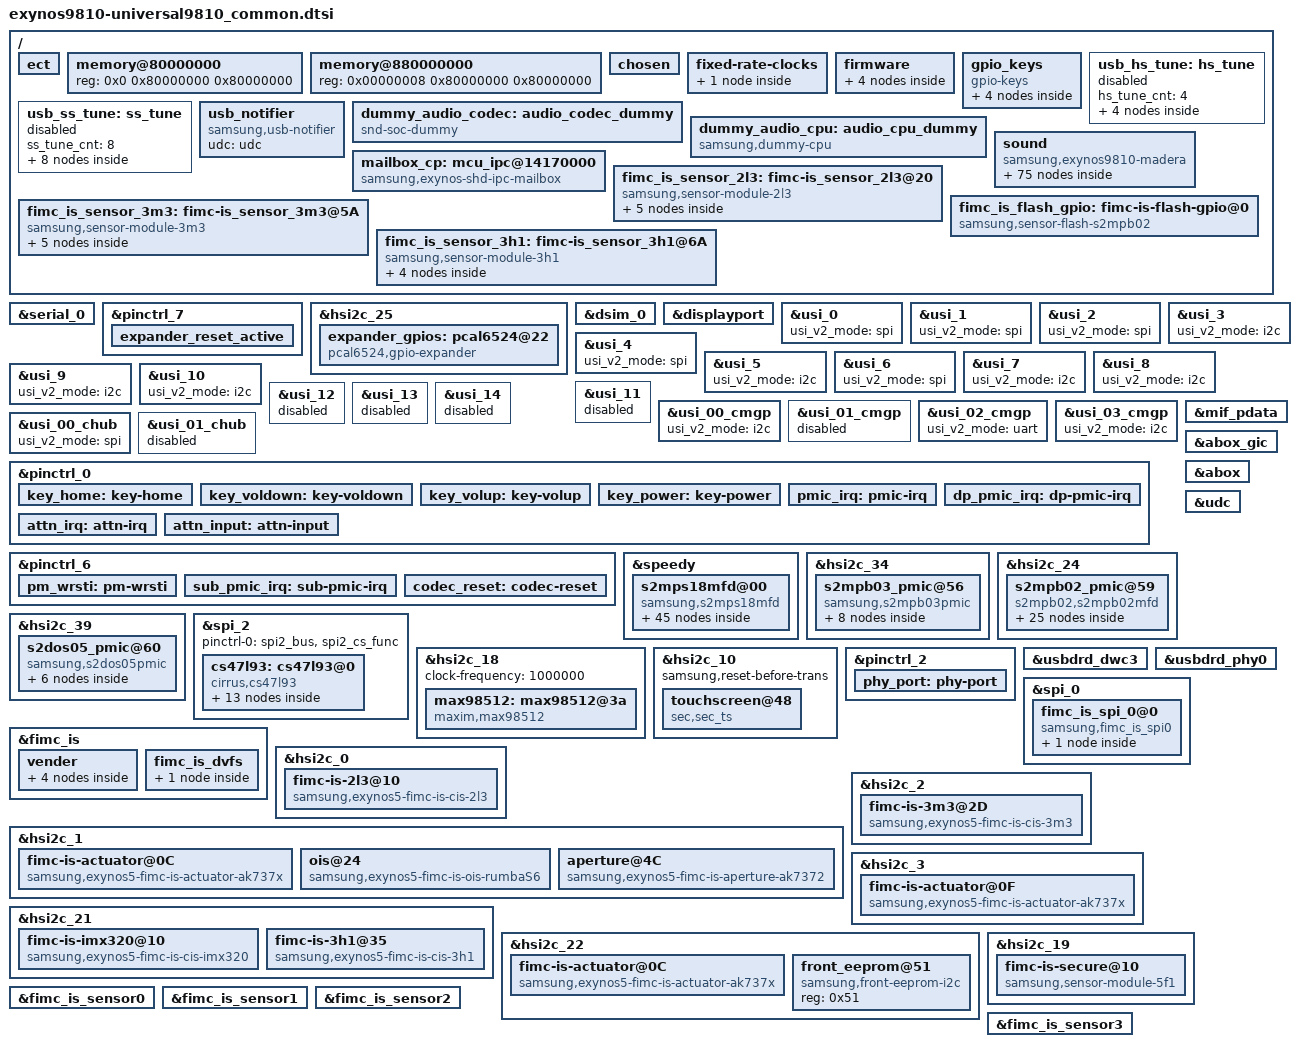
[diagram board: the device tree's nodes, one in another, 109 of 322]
/*
 * SAMSUNG EXYNOS9810 board device tree source
 *
 * Copyright (c) 2017 Samsung Electronics Co., Ltd.
 *		http://www.samsung.com
 *
 * This program is free software; you can redistribute it and/or modify
 * it under the terms of the GNU General Public License version 2 as
 * published by the Free Software Foundation.
*/

#include <dt-bindings/clock/exynos9810.h>
#include <dt-bindings/interrupt-controller/exynos9810.h>
#include <dt-bindings/camera/fimc_is.h>
#include "exynos9810-display-lcd.dtsi"
#include "modem-ss360ap-sipc-pdata.dtsi"

/ {
	fragment@common {
		target-path = "/";
		__overlay__ {
			#address-cells = <2>;
			#size-cells = <1>;
			ect {
				parameter_address = <0x90000000>;
				parameter_size = <0x32000>;
			};

			memory@80000000 {
				device_type = "memory";
				reg = <0x0 0x80000000 0x80000000>;
			};

			memory@880000000 {
				device_type = "memory";
				reg = <0x00000008 0x80000000 0x80000000>;
			};

			chosen {
//				bootargs = "earlycon=exynos4210,0x10440000 console=ttySAC0,115200n8 root=/dev/ram0 console=ttySAC0,115200n8 root=/dev/ram0 rw ramdisk=8192 initrd=0x84000000,8M init=/linuxrc clk_ignore_unused ess_setup=0x86000000";
//				bootargs = "console=ttySAC0 root=/dev/ram0 clk_ignore_unused androidboot.hardware=samsungexynos9810 androidboot.selinux=permissive androidboot.debug_level=0x4948 ecd_setup=disable pmic_info=0x3 ccic_info=0x1 firmware_class.path=/vendor/firmware reserve-fimc=0xffffff80fa000000 sec_debug.cp=0";
				bootargs = "console=ram root=/dev/ram0 clk_ignore_unused androidboot.hardware=samsungexynos9810 androidboot.selinux=permissive androidboot.debug_level=0x4948 ecd_setup=disable pmic_info=0x3 ccic_info=0x1 firmware_class.path=/vendor/firmware reserve-fimc=0xffffff80fa000000 sec_debug.cp=0";
				linux,initrd-start = <0x84000000>;
				linux,initrd-end = <0x841FFFFF>;
			};

			fixed-rate-clocks {
				oscclk {
					compatible = "samsung,exynos9810-oscclk";
					clock-frequency = <26000000>;
				};
			};
			firmware {
				android {
					compatible = "android,firmware";
					fstab {
						compatible = "android,fstab";
						system {
							compatible = "android,system";
							dev = "/dev/block/platform/11120000.ufs/by-name/system";
							type = "ext4";
							mnt_flags = "ro";
							fsmgr_flags = "wait";
						};
						vendor {
							compatible = "android,vendor";
							dev = "/dev/block/platform/11120000.ufs/by-name/vendor";
							type = "ext4";
							mnt_flags = "ro";
							fsmgr_flags = "wait";
						};
					};
				};
			};

			gpio_keys {
				status = "okay";
				compatible = "gpio-keys";
				pinctrl-names = "default";
				pinctrl-0 = <&key_home &key_voldown &key_volup &key_power>;
				button@1 {
					label = "gpio-keys: KEY_HOME";
					linux,code = <172>;
					gpios = <&gpa0 6 0xf>;
					gpio-key,wakeup = <1>;
				};
				button@2 {
					label = "gpio-keys: KEY_VOLUMEDOWN";
					linux,code = <114>;
					gpios = <&gpa0 4 0xf>;
				};
				button@3 {
					label = "gpio-keys: KEY_VOLUMEUP";
					linux,code = <115>;
					gpios = <&gpa0 3 0xf>;
				};
				button@4 {
					label = "gpio-keys: KEY_POWER";
					linux,code = <116>;
					gpios = <&gpa2 4 0xf>;
					gpio-key,wakeup = <1>;
				};
			};

			usb_hs_tune:hs_tune {
				status = "disabled";
				hs_tune_cnt = <4>;
				/* value = <device host> */
				hs_tune1 {
					tune_name = "tx_pre_emp";
					tune_value = <0x3 0x3>;
				};

				hs_tune2 {
					tune_name = "tx_vref";
					tune_value = <0x7 0x7>;
				};

				hs_tune3 {
					tune_name = "rx_sqrx";
					tune_value = <0x5 0x5>;
				};

				hs_tune4 {
					tune_name = "utmi_clk";
					tune_value = <0x1 0x1>;
				};
			};

			usb_ss_tune:ss_tune {
				status = "disabled";
				ss_tune_cnt = <8>;
				/* value = <device host> */
				ss_tune1 {
					tune_name = "sstx_deemph";
					tune_value = <0x6 0x6>;
				};

				ss_tune2 {
					tune_name = "sstx_amp";
					tune_value = <0x0 0x0>;
				};

				ss_tune3 {
					tune_name = "ssrx_los";
					tune_value = <0x4 0x4>;
				};

				ss_tune4 {
					tune_name = "ssrx_ctle_peak";
					tune_value = <0x7 0x7>;
				};

				ss_tune5 {
					tune_name = "ssrx_eq_code";
					tune_value = <0x5 0x5>;
				};

				ss_tune6 {
					tune_name = "ssrx_cur_ctrl";
					tune_value = <0x0 0x0>;
				};

				ss_tune7 {
					tune_name = "ssrx_eqen";
					tune_value = <0x3 0x3>;
				};

				ss_tune8 {
					tune_name = "sstx_boost";
					tune_value = <0x2 0x2>;
				};

			};

			usb_notifier {
				compatible = "samsung,usb-notifier";
				udc = <&udc>;
			};

			dummy_audio_codec: audio_codec_dummy {
				status = "okay";
				compatible = "snd-soc-dummy";
			};

			dummy_audio_cpu: audio_cpu_dummy {
				compatible = "samsung,dummy-cpu";
				status = "okay";
			};

			sound {
				status = "okay";
				compatible = "samsung,exynos9810-madera";

				clock-names = "xclkout";
				clocks = <&clock OSC_AUD>;

				cirrus,sysclk = <1 4 98304000>;
				cirrus,dspclk = <8 4 147456000>;
				cirrus,fll1-refclk = <1 0 26000000>;

				cirrus,asyncclk = <2 5 90316800>;
				cirrus,fll2-refclk = <2 1 32768>;

				samsung,routing = "HEADSETMIC", "MICBIAS2A",
					"IN1BL", "HEADSETMIC",
					"DMIC1", "MICBIAS1A",
					"IN3L", "DMIC1",
					"DMIC2", "MICBIAS1B",
					"IN2AL", "DMIC2",
					"DMIC3", "MICBIAS1C",
					"IN3R", "DMIC3",
					"VTS PAD DPDM", "DMIC1",
					"RECEIVER", "HPOUT4L",
					"RECEIVER", "HPOUT4R",
					"HEADPHONE", "HPOUT2L",
					"HEADPHONE", "HPOUT2R",
					"BLUETOOTH SPK", "ABOX UAIF3 Playback",
					"ABOX UAIF3 Capture", "BLUETOOTH MIC",
					"VOUTPUT", "ABOX UAIF0 Playback",
					"ABOX UAIF1 Capture", "VINPUT1",
					"SPEAKER", "HiFi Playback",
					"VOUTPUTCALL", "ABOX UAIF2 Playback",
					"ABOX UAIF2 Capture", "VINPUTCALL",
					"VTS Virtual Output", "VTS Virtual Output Mux",
					"VTS Virtual Output Mux", "DMIC1";

				samsung,codec = <&abox &abox_uaif_0 &abox_uaif_1 &abox_uaif_2
					&abox_uaif_3 &abox_dsif &vts>;
				samsung,aux = <&abox_effect>;

				rdma@0 {
					cpu {
						sound-dai = <&abox 0>;
					};
					codec {
						sound-dai = <&dummy_audio_codec>;
					};
				};
				rdma@1 {
					cpu {
						sound-dai = <&abox 1>;
					};
					codec {
						sound-dai = <&dummy_audio_codec>;
					};
				};
				rdma@2 {
					cpu {
						sound-dai = <&abox 2>;
					};
					codec {
						sound-dai = <&dummy_audio_codec>;
					};
				};
				rdma@3 {
					cpu {
						sound-dai = <&abox 3>;
					};
					codec {
						sound-dai = <&dummy_audio_codec>;
					};
				};
				rdma@4 {
					cpu {
						sound-dai = <&abox 4>;
					};
					codec {
						sound-dai = <&dummy_audio_codec>;
					};
				};
				rdma@5 {
					cpu {
						sound-dai = <&abox 5>;
					};
					codec {
						sound-dai = <&dummy_audio_codec>;
					};
				};
				rdma@6 {
					cpu {
						sound-dai = <&abox 6>;
					};
					codec {
						sound-dai = <&dummy_audio_codec>;
					};
				};
				rdma@7 {
					cpu {
						sound-dai = <&abox 7>;
					};
					codec {
						sound-dai = <&dummy_audio_codec>;
					};
				};
				wdma@0 {
					cpu {
						sound-dai = <&abox 8>;
					};
					codec {
						sound-dai = <&dummy_audio_codec>;
					};
				};
				wdma@1 {
					cpu {
						sound-dai = <&abox 9>;
					};
					codec {
						sound-dai = <&dummy_audio_codec>;
					};
				};
				wdma@2 {
					cpu {
						sound-dai = <&abox 10>;
					};
					codec {
						sound-dai = <&dummy_audio_codec>;
					};
				};
				wdma@3 {
					cpu {
						sound-dai = <&abox 11>;
					};
					codec {
						sound-dai = <&dummy_audio_codec>;
					};
				};
				wdma@4 {
					cpu {
						sound-dai = <&abox 12>;
					};
					codec {
						sound-dai = <&dummy_audio_codec>;
					};
				};
				vts@0 {
					cpu {
						sound-dai = <&dummy_audio_cpu>;//<&vts 0>;
					};
					codec {
						sound-dai = <&dummy_audio_codec>;
					};
				};
				vts@1 {
					cpu {
						sound-dai = <&dummy_audio_cpu>;//<&vts 1>;
					};
					codec {
						sound-dai = <&dummy_audio_codec>;
					};
				};
				dp_audio@0 {
					cpu {
						sound-dai = <&dummy_audio_cpu>;
					};
					codec {
						sound-dai = <&dummy_audio_codec>;
					};
				};
				uaif@0 {
					cpu {
						sound-dai = <&abox_uaif_0>;
					};
					codec {
						sound-dai = <&cs47l93 0>;
					};
				};
				uaif@1 {
					cpu {
						sound-dai = <&abox_uaif_1>;
					};
					codec {
						sound-dai = <&max98512 0>;
					};
				};
				uaif@2 {
					cpu {
						sound-dai = <&abox_uaif_2>;
					};
					codec {
						sound-dai = <&dummy_audio_codec>;
					};
				};
				uaif@3 {
					cpu {
						sound-dai = <&abox_uaif_3>;
					};
					codec {
						sound-dai = <&dummy_audio_codec>;
					};
				};
				dsif@0 {
					cpu {
						sound-dai = <&abox_dsif>;
					};
					codec {
						sound-dai = <&dummy_audio_codec>;
					};
				};
				sifs0@0 {
					cpu {
						sound-dai = <&abox 13>;
					};
					codec {
						sound-dai = <&dummy_audio_codec>;
					};
				};
				sifs1@0 {
					cpu {
						sound-dai = <&abox 14>;
					};
					codec {
						sound-dai = <&dummy_audio_codec>;
					};
				};
				sifs2@0 {
					cpu {
						sound-dai = <&abox 15>;
					};
					codec {
						sound-dai = <&dummy_audio_codec>;
					};
				};
				debug-trace@1 {
					cpu {
						sound-dai = <&cs47l93 6>;
					};
					codec {
						sound-dai = <&cs47l93 7>;
					};
				};
			};

			mailbox_cp: mcu_ipc@14170000 {
				compatible = "samsung,exynos-shd-ipc-mailbox";
				reg = <0x0 0x14170000 0x180>;
				mcu,name = "mcu_ipc_cp";
				mcu,id = <0>;
				interrupts = <0 INTREQ__MAILBOX_CP2AP 0 >;
				mcu,irq_affinity_mask = <3>;
			};

			/* REAR CAMERA */
			fimc_is_sensor_2l3: fimc-is_sensor_2l3@20 {
				compatible = "samsung,sensor-module-2l3";

				pinctrl-names = "pin0", "pin1", "pin2", "release";
				pinctrl-0 = <>;
				pinctrl-1 = <&fimc_is_mclk0_out>;
				pinctrl-2 = <&fimc_is_mclk0_fn>;
				pinctrl-3 = <>;

				position = <0>;	/* Rear:0. Front:1. Rear_sub:2. Secure:3. */
				id = <0>; /* fimc_is_sensor id */
				mclk_ch = <0>;
				sensor_i2c_ch = <0>; /* SENSOR_CONTROL_I2C0 */

				gpio_mclk = <&gpc1 4 0x1>;
				gpio_reset = <&gpg2 6 0x1>; /* sensor reset */
				gpio_ois_reset = <&gpg0 6 0x1>; /* ois reset */

				status = "okay";

				af {
					product_name = <18>; /* ACTUATOR_NAME_AK737X : ak7371 or ak7374 */
					i2c_ch = <1>; /* SENSOR_CONTROL_I2C1 */
				};

				flash {
					product_name = <11>; /* FLASH_GPIO */
				};

				ois {
					product_name = <2>; /* RUMBA-S6 */
					i2c_addr = <0x48>;
					i2c_ch = <1>; /* SENSOR_CONTROL_I2C1 */
				};

				aperture {
					product_name = <1>; /* ak7372 */
					i2c_addr = <0x98>;
					i2c_ch = <1>; /* SENSOR_CONTROL_I2C1 */
				};

				internal_vc {
					/* vc_list = <channel, data_type, buffer_offset>
					 * channel : Output VC channel
					 *  - Supported channels are 1(VC1), 2(VC2), 3(VC3)
					 *  - Since channel 0(VC0) is dedicated to image data, it can not be used

					 * data_type : Output type of VC channel
					 *  - Value 0 VC_NOTHING
					 *  - Value 1 VC_TAILPDAF
					 *  - Value 2 VC_MIPISTAT
					 *  - Value 3 VC_EMBEDDED
					 * buffer_offset : get_vc_dma_buf offset value of buffer to return when using interface

					 *  - Value 0 N buffer return
					 *  - Value 1 N-1 buffer return
					 */

					vc_list = <2 VC_MIPISTAT 0 3 VC_EMBEDDED 0>; /* channel, type, offset */
				};
			};

			fimc_is_sensor_3m3: fimc-is_sensor_3m3@5A {
				compatible = "samsung,sensor-module-3m3";

				pinctrl-names = "pin0", "pin1", "pin2", "release";
				pinctrl-0 = <>;
				pinctrl-1 = <>;
				pinctrl-2 = <>;
				pinctrl-3 = <>;

				position = <2>; /* Rear:0. Front:1, Tele:2 */
				id = <2>; /* fimc_is_sensor id */
				mclk_ch = <0>;
				sensor_i2c_ch = <2>; /* SENSOR_CONTROL_I2C2 */

				gpio_mclk = <&gpc1 4 0x1>; /* mclk shared with wide-cam */
				gpio_reset = <&gpg2 7 0x1>; /* sensor reset */
				gpio_ois_reset = <&gpg0 6 0x1>; /* ois reset */

				status = "okay";

				af {
					product_name = <18>; /* ACTUATOR_NAME_AK737X : ak7371 or ak7374 */
					i2c_ch = <3>; /* SENSOR_CONTROL_I2C3 */
				};

				flash {
					product_name = <11>; /* FLASH_GPIO */
				};

				preprocessor {
					product_name = <100>; /* NOTHING */
				};

				ois {
					product_name = <2>; /* RUMBA-S6 */
					i2c_addr = <0x48>;
					i2c_ch = <1>; /* I2C 1 */
				};

				internal_vc {
					/* vc_list = <channel, data_type, buffer_offset>
					 * channel : Output VC channel
					 *  - Supported channels are 1(VC1), 2(VC2), 3(VC3)
					 *  - Since channel 0(VC0) is dedicated to image data, it can not be used

					 * data_type : Output type of VC channel
					 *  - Value 0 VC_NOTHING
					 *  - Value 1 VC_TAILPDAF
					 *  - Value 2 VC_MIPISTAT
					 *  - Value 3 VC_EMBEDDED
					 * buffer_offset : get_vc_dma_buf offset value of buffer to return when using interface

					 *  - Value 0 N buffer return
					 *  - Value 1 N-1 buffer return
					 */

					vc_list = <1 VC_TAILPDAF 0>; /* channel, type, offset */
				};
			};

			fimc_is_flash_gpio: fimc-is-flash-gpio@0 {
				compatible = "samsung,sensor-flash-s2mpb02";
				id = <0 2>;
				status = "okay";

				torch-gpio = <&gpg2 4 0x1>;
				flash-gpio = <&gpg3 5 0x1>;
			};

			/* FRONT CAMERA */
			fimc_is_sensor_3h1: fimc-is_sensor_3h1@6A {
				compatible = "samsung,sensor-module-3h1";

				pinctrl-names = "pin0", "pin1", "pin2", "release";
				pinctrl-0 = <>;
				pinctrl-1 = <&fimc_is_mclk1_out>;
				pinctrl-2 = <&fimc_is_mclk1_fn>;
				pinctrl-3 = <>;

				position = <1>;	/* Rear:0. Front:1. Rear_sub:2. Secure:3. */
				id = <1>; /* fimc_is_sensor id */
				mclk_ch = <1>;
				sensor_i2c_ch = <4>; /* SENSOR_CONTROL_I2C4 */

				gpio_mclk = <&gpc1 5 0x1>;
				gpio_reset = <&gpg2 5 0x1>; /* sensor reset */
				status = "okay";

				af {
					product_name = <18>; /* ACTUATOR_NAME_AK737X : ak7372 */
					i2c_ch = <5>; /* SENSOR_CONTROL_I2C5 */
				};

				flash {
					product_name = <100>; /* NOTHING */
				};

				ois {
					product_name = <100>; /* NOTHING */
				};

				internal_vc {
					/* DUMMY */
				};
			};
		}; /* end of __overlay__ */
	}; /* end of fragment */
}; /* end of root */
&serial_0 {
	status = "okay";
};

/***** reference symbol node *****/
&pinctrl_7 {
expander_reset_active: expander_reset_active {
	       samsung,pins = "gpg3-6";
	       samsung,pin-function = <1>;
	       samsung,pin-pud = <0>;
	       samsung,pin-val = <1>;
       };
};

&hsi2c_25 {
	#address-cells = <1>;
	#size-cells = <0>;
	status = "okay";
	expander_gpios: pcal6524@22 {
		compatible = "pcal6524,gpio-expander";
		gpio-controller;
		#gpio-cells = <2>;
		reg = <0x22>;
		pinctrl-names = "expander_reset_setting";
		pinctrl-0 = <&expander_reset_active>;
		pcal6524,gpio_start = <300>;
		pcal6524,ngpio = <24>;
		pcal6524,reset-gpio = <&gpg3 6 0>;
		pcal6524,support_initialize = <1>;
		/* config, 24 ~ 0, 1bit configure[1:input, 0:output]*/
		pcal6524,config = <0xFFFFFF>;    /* P2[11111111] P1[11111111] P0[11111111] */
		/* data_out, 24 ~ 0, 1bit configure[1:high, 0:low]*/
		pcal6524,data_out = <0x000000>;  /* P2[00000000] P1[00000000] P0[00000000] */
		/* pull_reg, 8 ~ 0, 2bit configure[00:no_pull, 01:pull_down, 10:pull_up, 11:not used] */
		pcal6524,pull_reg_p0 = <0x0000>; /* 00 00 00 00 / 00 00 00 00 */
		pcal6524,pull_reg_p1 = <0x0000>; /* 00 00 00 00 / 00 00 00 00 */
		pcal6524,pull_reg_p2 = <0x0000>; /* 00 00 00 00 / 00 00 00 00 */
	};
};

&dsim_0 {
	lcd_info = <&s6e3ha8>;
	/* reset */
	gpios = <&gpa3 4 0x1>;
};

&displayport {
	dp,aux_sw_oe = <&expander_gpios 4 0>;
	dp,sbu_sw_sel = <&expander_gpios 1 0>;
	dp,usb_con_sel = <&gph0 6 0>;

	pinctrl-names = "default";
};

&usi_0 {
	usi_v2_mode = "spi";
	status = "okay";
};

&usi_1 {
	usi_v2_mode = "spi";
	status = "okay";
};

&usi_2 {
	usi_v2_mode = "spi";
	status = "okay";
};

&usi_3 {
	usi_v2_mode = "i2c";
	status = "okay";
};

&usi_4 {
	usi_v2_mode = "spi";
	status = "okay";
};

&usi_5 {
	usi_v2_mode = "i2c";
	status = "okay";
};

&usi_6 {
	usi_v2_mode = "spi";
	status = "okay";
};

&usi_7 {
	usi_v2_mode = "i2c";
	status = "okay";
};

&usi_8 {
	usi_v2_mode = "i2c";
	status = "okay";
};

&usi_9 {
	usi_v2_mode = "i2c";
	status = "okay";
};

&usi_10 {
	usi_v2_mode = "i2c";
	status = "okay";
};

&usi_11 {
	status = "disabled";
};

&usi_12 {
	status = "disabled";
};

&usi_13 {
	status = "disabled";
};

&usi_14 {
	status = "disabled";
};

&usi_00_cmgp {
	usi_v2_mode = "i2c";
	status = "okay";
};

/* USI_01_CMGP */
&usi_01_cmgp {
	status = "disabled";
};

/* USI_02_CMGP */
&usi_02_cmgp {
	usi_v2_mode = "uart";
	status = "okay";
};

/* USI_03_CMGP */
&usi_03_cmgp {
	usi_v2_mode = "i2c";
	status = "okay";
};

/* USI_00_CHUB */
&usi_00_chub {
	usi_v2_mode = "spi";
	status = "okay";
};

/* USI_01_CHUB */
&usi_01_chub {
	status = "disabled";
};

&pinctrl_0 {
	key_home: key-home {
		samsung,pins = "gpa0-6";
		samsung,pin-function = <0xf>;
		samsung,pin-pud = <0>;
		samsung,pin-drv = <0>;
	};

	key_voldown: key-voldown {
		samsung,pins = "gpa0-4";
		samsung,pin-function = <0xf>;
		samsung,pin-pud = <0>;
		samsung,pin-drv = <0>;
	};

	key_volup: key-volup {
		samsung,pins = "gpa0-3";
		samsung,pin-function = <0xf>;
		samsung,pin-pud = <0>;
		samsung,pin-drv = <0>;
	};

	key_power: key-power {
		samsung,pins = "gpa2-4";
		samsung,pin-function = <0xf>;
	};

	pmic_irq: pmic-irq {
		samsung,pins = "gpa0-1";
		samsung,pin-pud = <3>;
		samsung,pin-drv = <3>;
	};

	dp_pmic_irq: dp-pmic-irq {
		samsung,pins = "gpa1-4";
		samsung,pin-function = <0>;
		samsung,pin-pud = <0>;
		samsung,pin-drv = <0>;
	};

	attn_irq: attn-irq {
		samsung,pins = "gpa1-0";
		samsung,pin-function = <0xf>;
		samsung,pin-pud = <0>;
		samsung,pin-drv = <0>;
	};
	attn_input: attn-input {
		samsung,pins = "gpa1-0";
		samsung,pin-function = <0>;
		samsung,pin-pud = <1>;
	};

};

&pinctrl_6 {
	/* Warm reset information from AP */
	pm_wrsti: pm-wrsti {
		samsung,pins = "gpg0-1";
		samsung,pin-con-pdn = <3>;
	};
	sub_pmic_irq: sub-pmic-irq {
		samsung,pins = "gpg2-1";
		samsung,pin-function = <0>;
		samsung,pin-pud = <0>;
		samsung,pin-drv = <0>;
	};

	codec_reset: codec-reset {
		samsung,pins ="gpg1-0";
		samsung,pin-con-pdn =<3>;
		samsung,pin-pud-pdn = <1>;
	};
};

&speedy {
	#address-cells = <1>;
	#size-cells = <0>;
	status = "okay";
	s2mps18mfd@00 {
		compatible = "samsung,s2mps18mfd";
		acpm-ipc-channel = <2>;
		i2c-speedy-address;
		s2mps18,wakeup = "enabled";
		s2mps18,irq-gpio = <&gpa0 1 0>;
		reg = <0x00>;
		interrupts = <1 0 0>;
		interrupt-parent = <&gpa0>;
		pinctrl-names = "default";
		pinctrl-0 = <&pmic_irq &pm_wrsti &smpl_warn>;
		gpios = <&gpg0 3 0>;
		smpl_warn_en = <1>; /* 1 : enable , 0 : disable */
		/* range of smpl_warn_vth */
		/* 0x00 : 2.1V, 0x20 : 2.3V, 0x40 : 2.5V, 0x60 : 2.7V 0x80 : 2.9V */
		/* 0xA0 : 3.1V, 0xC0 : 3.3V, 0xE0 : 3.5V */
		smpl_warn_vth = <0x80>;
		/* LowBat_Hys[4:3] 00(100mV), 01(200mV), 10(300mV), 11(400mV) */
		smpl_warn_hys = <0x00>;
		adc_mode = <1>; /* 0 : disable, 1 : current meter, 2 : power meter */
		adc_sync_mode = <2>; /* 1 : sync mode, 2 : async mode */
		g3d_en = <1>; /* 1 : enable , 0 : disable */
		cpu_ocp_warn_en = <1>; /* 1 : enable, 0 : disable */
		cpu_ocp_warn_reset = <0>; /* 0 : 2 clock, 1 : 32 clock */
		cpu_ocp_warn_lv = <0x0>; /* step : -250mA */
		gpu_ocp_warn_en = <1>; /* 1: enable, 0 : disable */
		gpu_ocp_warn_reset = <1>; /* 0 : 2 clock, 1 : 32 clock */
		gpu_ocp_warn_lv = <0x0>; /* step : -166mA */
		/* RTC: wtsr/smpl */
		wtsr_en = "enabled"; /* enable */
		smpl_en = "enabled"; /* enable */
		wtsr_timer_val = <3>;	/* 1000ms */
		smpl_timer_val = <4>;	/* 500ms */
		check_jigon = <0>; /* do not check jigon */
		/* RTC: If it's first boot, reset rtc to 1/1/2017 12:00:00(Sun) */
		init_time,sec = <0>;
		init_time,min = <0>;
		init_time,hour = <12>;
		init_time,mday = <1>;
		init_time,mon = <0>;
		init_time,year = <117>;
		init_time,wday = <0>;

		regulators {
			buck1_reg: BUCK1 {
				regulator-name = "vdd_mif";
				regulator-min-microvolt = <450000>;
				regulator-max-microvolt = <950000>;
				regulator-always-on;
				regulator-ramp-delay = <12000>;
				regulator-initial-mode = <2>;
			};
			buck2_reg: BUCK2 {
				regulator-name = "vdd_cpucl1";
				regulator-min-microvolt = <450000>;
				regulator-max-microvolt = <1300000>;
				regulator-always-on;
				regulator-ramp-delay = <6000>;
				regulator-initial-mode = <1>;
			};

			buck3_reg: BUCK3 {
				regulator-name = "vdd_cpucl0";
				regulator-min-microvolt = <450000>;
				regulator-max-microvolt = <1300000>;
				regulator-always-on;
				regulator-ramp-delay = <12000>;
				regulator-initial-mode = <1>;
			};

			buck4_reg: BUCK4{
				regulator-name = "vdd_int";
				regulator-min-microvolt = <450000>;
				regulator-max-microvolt = <950000>;
				regulator-always-on;
				regulator-ramp-delay = <12000>;
				regulator-initial-mode = <2>;
			};

			buck5_reg: BUCK5 {
				regulator-name = "vdd_cam";
				regulator-min-microvolt = <450000>;
				regulator-max-microvolt = <950000>;
				regulator-always-on;
				regulator-ramp-delay = <12000>;
				regulator-initial-mode = <2>;
			};

			buck6_reg: BUCK6 {
				regulator-name = "vdd_g3d";
				regulator-min-microvolt = <450000>;
				regulator-max-microvolt = <950000>;
				regulator-always-on;
				regulator-ramp-delay = <12000>;
				regulator-initial-mode = <2>;
			};

			buck7_reg: BUCK7 {
				regulator-name = "vdd_cpucl1_m";
				regulator-min-microvolt = <450000>;
				regulator-max-microvolt = <1300000>;
				regulator-always-on;
				regulator-ramp-delay = <6000>;
				regulator-initial-mode = <1>;
			};

			buck8_reg: BUCK8 {
				regulator-name = "vdd2_mem";
				regulator-min-microvolt = <900000>;
				regulator-max-microvolt = <1300000>;
				regulator-always-on;
				regulator-ramp-delay = <12000>;
				regulator-initial-mode = <3>;
			};

			buck9_reg: BUCK9 {
				regulator-name = "vddq_mem";
				regulator-min-microvolt = <450000>;
				regulator-max-microvolt = <950000>;
				regulator-always-on;
				regulator-ramp-delay = <12000>;
				regulator-initial-mode = <2>;
			};

			buck10_reg: BUCK10 {
				regulator-name = "vdd_lldo1";
				regulator-min-microvolt = <750000>;
				regulator-max-microvolt = <1150000>;
				regulator-always-on;
				regulator-ramp-delay = <12000>;
				regulator-initial-mode = <3>;
			};

			buck11_reg: BUCK11 {
				regulator-name = "vdd_lldo2";
				regulator-min-microvolt = <900000>;
				regulator-max-microvolt = <1300000>;
				regulator-always-on;
				regulator-ramp-delay = <12000>;
				regulator-initial-mode = <3>;
			};

			buck12_reg: BUCK12 {
				regulator-name = "vdd_lldo3";
				regulator-min-microvolt = <1100000>;
				regulator-max-microvolt = <1500000>;
				regulator-always-on;
				regulator-ramp-delay = <12000>;
				regulator-initial-mode = <3>;
			};

			buck13_reg: BUCK13 {
				regulator-name = "vdd_mldo";
				regulator-min-microvolt = <1750000>;
				regulator-max-microvolt = <2150000>;
				regulator-always-on;
				regulator-ramp-delay = <12000>;
				regulator-initial-mode = <3>;
			};

			ldo1_reg: LDO1 {
				regulator-name = "vdd_ldo1";
				regulator-min-microvolt = <700000>;
				regulator-max-microvolt = <950000>;
				regulator-always-on;
				regulator-ramp-delay = <12000>;
				regulator-initial-mode = <3>;
			};

			ldo2_reg: LDO2 {
				regulator-name = "vqmmc";
				regulator-min-microvolt = <1700000>;
				regulator-max-microvolt = <3300000>;
				regulator-ramp-delay = <12000>;
			};

			ldo3_reg: LDO3 {
				regulator-name = "vdd_ldo3";
				regulator-min-microvolt = <1600000>;
				regulator-max-microvolt = <1950000>;
				regulator-always-on;
				regulator-ramp-delay = <12000>;
				regulator-initial-mode = <3>;
			};

			ldo4_reg: LDO4 {
				regulator-name = "vdd_ldo4";
				regulator-min-microvolt = <700000>;
				regulator-max-microvolt = <1100000>;
				regulator-always-on;
				regulator-ramp-delay = <12000>;
				regulator-initial-mode = <1>;
			};

			ldo5_reg: LDO5 {
				regulator-name = "vdd_ldo5";
				regulator-min-microvolt = <1600000>;
				regulator-max-microvolt = <1950000>;
				regulator-always-on;
				regulator-ramp-delay = <12000>;
				regulator-initial-mode = <1>;
			};

			ldo6_reg: LDO6 {
				regulator-name = "vdd_ldo6";
				regulator-min-microvolt = <450000>;
				regulator-max-microvolt = <950000>;
				regulator-always-on;
				regulator-ramp-delay = <12000>;
				regulator-initial-mode = <1>;
			};

			ldo7_reg: LDO7 {
				regulator-name = "vdd_ldo7";
				regulator-min-microvolt = <450000>;
				regulator-max-microvolt = <950000>;
				regulator-always-on;
				regulator-ramp-delay = <12000>;
				regulator-initial-mode = <1>;
			};

			ldo8_reg: LDO8 {
				regulator-name = "vdd_ldo8";
				regulator-min-microvolt = <700000>;
				regulator-max-microvolt = <1300000>;
				regulator-always-on;
				regulator-ramp-delay = <12000>;
				regulator-initial-mode = <1>;
			};

			ldo9_reg: LDO9 {
				regulator-name = "vdd_ldo9";
				regulator-min-microvolt = <1600000>;
				regulator-max-microvolt = <1950000>;
				regulator-always-on;
				regulator-ramp-delay = <12000>;
				regulator-initial-mode = <1>;
			};

			ldo10_reg: LDO10 {
				regulator-name = "vdd_ldo10";
				regulator-min-microvolt = <450000>;
				regulator-max-microvolt = <950000>;
				regulator-always-on;
				regulator-ramp-delay = <12000>;
				regulator-initial-mode = <1>;
			};

			ldo11_reg: LDO11 {
				regulator-name = "vdd_ldo11";
				regulator-min-microvolt = <450000>;
				regulator-max-microvolt = <950000>;
				regulator-always-on;
				regulator-ramp-delay = <12000>;
				regulator-initial-mode = <1>;
			};

			ldo12_reg: LDO12 {
				regulator-name = "vdd_ldo12";
				regulator-min-microvolt = <700000>;
				regulator-max-microvolt = <1100000>;
				regulator-always-on;
				regulator-ramp-delay = <12000>;
				regulator-initial-mode = <1>;
			};

			ldo13_reg: LDO13 {
				regulator-name = "vdd_ldo13";
				regulator-min-microvolt = <1600000>;
				regulator-max-microvolt = <1950000>;
				regulator-always-on;
				regulator-ramp-delay = <12000>;
				regulator-initial-mode = <1>;
			};

			ldo14_reg: LDO14 {
				regulator-name = "vdd_ldo14";
				regulator-min-microvolt = <1700000>;
				regulator-max-microvolt = <3350000>;
				regulator-always-on;
				regulator-ramp-delay = <12000>;
				regulator-initial-mode = <1>;
			};

			ldo22_reg: LDO22 {
				regulator-name = "vdd_ldo22";
				regulator-min-microvolt = <700000>;
				regulator-max-microvolt = <1100000>;
				regulator-ramp-delay = <12000>;
				regulator-initial-mode = <0>;
			};

			ldo30_reg: LDO30 {
				regulator-name = "vdd_ldo30";
				regulator-min-microvolt = <450000>;
				regulator-max-microvolt = <1100000>;
				regulator-always-on;
				regulator-ramp-delay = <12000>;
				regulator-initial-mode = <1>;
			};

			ldo31_reg: LDO31 {
				regulator-name = "vmmc";
				regulator-min-microvolt = <1800000>;
				regulator-max-microvolt = <3375000>;
				regulator-ramp-delay = <12000>;
			};

			ldo32_reg: LDO32 {
				regulator-name = "vdd_ldo32";
				regulator-min-microvolt = <1800000>;
				regulator-max-microvolt = <3375000>;
				regulator-always-on;
				regulator-ramp-delay = <12000>;
				regulator-initial-mode = <2>;
			};

			ldo33_reg: LDO33 {
				regulator-name = "vdd_ldo33";
				regulator-min-microvolt = <1000000>;
				regulator-max-microvolt = <2275000>;
				regulator-always-on;
				regulator-ramp-delay = <12000>;
				regulator-initial-mode = <2>;
			};

			ldo34_reg: LDO34 {
				regulator-name = "vdd_ldo34";
				regulator-min-microvolt = <700000>;
				regulator-max-microvolt = <1300000>;
				regulator-always-on;
				regulator-ramp-delay = <12000>;
				regulator-initial-mode = <2>;
			};

			ldo35_reg: LDO35 {
				regulator-name = "tsp_io";
				regulator-min-microvolt = <1800000>;
				regulator-max-microvolt = <1800000>;
				regulator-boot-on;
			};

			ldo36_reg: LDO36 {
				regulator-name = "vdd_ldo36";
				regulator-min-microvolt = <1800000>;
				regulator-max-microvolt = <3375000>;
				regulator-always-on;
				regulator-ramp-delay = <12000>;
				regulator-initial-mode = <2>;
			};

			ldo37_reg: LDO37 {
				regulator-name = "vdd_ldo37";
				regulator-min-microvolt = <1000000>;
				regulator-max-microvolt = <2275000>;
				regulator-always-on;
				regulator-ramp-delay = <12000>;
				regulator-initial-mode = <2>;
			};

			ldo38_reg: LDO38 {
				regulator-name = "vdd_ldo38";
				regulator-min-microvolt = <1000000>;
				regulator-max-microvolt = <2275000>;
				regulator-always-on;
				regulator-ramp-delay = <12000>;
				regulator-initial-mode = <2>;
			};

			ldo39_reg: LDO39 {
				regulator-name = "VDDD_1.05V_IRIS";
				regulator-min-microvolt = <1000000>;
				regulator-max-microvolt = <1050000>;
			};

			ldo40_reg: LDO40 {
				regulator-name = "VDDA_2.8V_IRIS";
				regulator-min-microvolt = <2800000>;
				regulator-max-microvolt = <2800000>;
			};

			ldo41_reg: LDO41 {
				regulator-name = "VDDIO_1.8V_IRIS";
				regulator-min-microvolt = <1800000>;
				regulator-max-microvolt = <1800000>;
			};

			ldo42_reg: LDO42 {
				regulator-name = "vdd_ldo42";
				regulator-min-microvolt = <1800000>;
				regulator-max-microvolt = <3375000>;
				regulator-always-on;
				regulator-ramp-delay = <12000>;
				regulator-initial-mode = <2>;
			};

			ldo43_reg: LDO43 {
				regulator-name = "tsp_avdd";
				regulator-min-microvolt = <3000000>;
				regulator-max-microvolt = <3000000>;
				regulator-boot-on;
			};

			ldo44_reg: LDO44 {
				regulator-name = "vdd_ldo44";
				regulator-min-microvolt = <1800000>;
				regulator-max-microvolt = <3375000>;
				regulator-always-on;
				regulator-ramp-delay = <12000>;
				regulator-initial-mode = <2>;
			};

			ldo45_reg: LDO45 {
				regulator-name = "vdd_ldo45";
				regulator-min-microvolt = <1800000>;
				regulator-max-microvolt = <3375000>;
				regulator-always-on;
				regulator-ramp-delay = <12000>;
				regulator-initial-mode = <2>;
			};
		};
	};
};

&mif_pdata {
	/* GPIOs for HW REV */
	/* XGPIO27-CP_REV0, XGPIO26-CP_REV1, XGPIO25-CP_REV2, XGPIO24-CP_REV3
	* XGPIO13-AP_REV0, XGPIO12-AP_REV1, XGPIO11-AP_REV2, XGPIO10-AP_REV3
	* XGPIO09-AP_REV3 */
	gpios = <&gpg3 3 0>, <&gpg3 2 0>, <&gpg3 1 0>, <&gpg3 0 0>,
		<&gpg1 5 0>, <&gpg1 4 0>, <&gpg1 3 0>, <&gpg1 2 0>,
		<&gpg1 1 0>;
	pinctrl-names = "default";
};

&hsi2c_34 {
	#address-cells = <1>;
	#size-cells = <0>;
	status = "okay";
	s2mpb03_pmic@56 {
		compatible = "samsung,s2mpb03pmic";
		reg = <0x56>;

		s2mpb03,wakeup;

		regulators {
			__ldo1_reg: s2mpb03-ldo1 {
				regulator-name = "VDDD_1.0V_CAM";
				regulator-min-microvolt = <975000>;
				regulator-max-microvolt = <1025000>;
			};

			__ldo2_reg: s2mpb03-ldo2 {
				regulator-name = "VDDQ_1.1V_CAM";
				regulator-min-microvolt = <1100000>;
				regulator-max-microvolt = <1100000>;
			};

			__ldo3_reg: s2mpb03-ldo3 {
				regulator-name = "VDDIO_1.8V_CAM";
				regulator-min-microvolt = <1800000>;
				regulator-max-microvolt = <1800000>;
			};

			__ldo4_reg: s2mpb03-ldo4 {
				regulator-name = "VDDD_RET_1.0V_CAM";
				regulator-min-microvolt = <700000>;
				regulator-max-microvolt = <1025000>;
			};

			__ldo5_reg: s2mpb03-ldo5 {
				regulator-name = "VDDA_2.15V_CAM";
				regulator-min-microvolt = <2150000>;
				regulator-max-microvolt = <2150000>;
			};

			__ldo6_reg: s2mpb03-ldo6 {
				regulator-name = "VDDA_2.95V_CAM";
				regulator-min-microvolt = <2950000>;
				regulator-max-microvolt = <2950000>;
			};

			__ldo7_reg: s2mpb03-ldo7 {
				regulator-name = "VDD_VM_2.8V_OIS";
				regulator-min-microvolt = <2800000>;
				regulator-max-microvolt = <2800000>;
			};
		};
	};
};

&hsi2c_24 {
	#address-cells = <1>;
	#size-cells = <0>;
	status = "okay";
	s2mpb02_pmic@59 {
		compatible = "s2mpb02,s2mpb02mfd";
		reg = <0x59>;

		s2mpb02,wakeup;
		pinctrl-names = "default";
		pinctrl-0 = <&sub_pmic_irq>;

		regulators {
			_buck1_reg: s2mpb02-buck1 {
				regulator-name = "VDD_EXT_1P3_PB03";
				regulator-min-microvolt = <1300000>;
				regulator-max-microvolt = <1300000>;
				regulator-always-on;
				regulator-boot-on;
			};

			_buck2_reg: s2mpb02-buck2 {
				regulator-name = "VDD_EXT_1P3_PB02";
				regulator-min-microvolt = <1300000>;
				regulator-max-microvolt = <1300000>;
				regulator-always-on;
				regulator-boot-on;
			};

			_buckboost_reg: s2mpb02-bb {
				regulator-name = "VREG_BOOST_BYP";
				regulator-min-microvolt = <2600000>;
				regulator-max-microvolt = <4000000>;
				regulator-always-on;
				regulator-boot-on;
			};

			_ldo1_reg: s2mpb02-ldo1 {
				regulator-name = "S2MPB02_LDO1";
				regulator-min-microvolt = <900000>;
				regulator-max-microvolt = <900000>;
			};

			_ldo2_reg: s2mpb02-ldo2 {
				regulator-name = "S2MPB02_LDO2";
				regulator-min-microvolt = <1000000>;
				regulator-max-microvolt = <1000000>;
			};

			_ldo3_reg: s2mpb02-ldo3 {
				regulator-name = "VDDD_1.05V_SUB";
				regulator-min-microvolt = <1000000>;
				regulator-max-microvolt = <1050000>;
			};

			_ldo4_reg: s2mpb02-ldo4 {
				regulator-name = "S2MPB02_LDO4";
				regulator-min-microvolt = <1200000>;
				regulator-max-microvolt = <1200000>;
			};

			_ldo5_reg: s2mpb02-ldo5 {
				regulator-name = "VDDD_1.05V_VT";
				regulator-min-microvolt = <1000000>;
				regulator-max-microvolt = <1050000>;
			};

			_ldo6_reg: s2mpb02-ldo6 {
				regulator-name = "VDDIO_1.8V_VT";
				regulator-min-microvolt = <1800000>;
				regulator-max-microvolt = <1800000>;
			};

			_ldo7_reg: s2mpb02-ldo7 {
				regulator-name = "VDDIO_1.8V_SUB";
				regulator-min-microvolt = <1800000>;
				regulator-max-microvolt = <1800000>;
			};

			_ldo8_reg: s2mpb02-ldo8 {
				regulator-name = "VDD_HRM_1P8";
				regulator-min-microvolt = <1800000>;
				regulator-max-microvolt = <1800000>;
			};

			_ldo9_reg: s2mpb02-ldo9 {
				regulator-name = "S2MPB02_LDO9";
				regulator-min-microvolt = <1800000>;
				regulator-max-microvolt = <1800000>;
			};

			_ldo10_reg: s2mpb02-ldo10 {
				regulator-name = "VDDD_1.8V_OIS";
				regulator-min-microvolt = <1800000>;
				regulator-max-microvolt = <1800000>;
			};

			_ldo11_reg: s2mpb02-ldo11 {
				regulator-name = "VDDA_2.8V_SUB";
				regulator-min-microvolt = <2800000>;
				regulator-max-microvolt = <2800000>;
			};

			_ldo12_reg: s2mpb02-ldo12 {
				regulator-name = "VDDAF_2.8V_SUB";
				regulator-min-microvolt = <2800000>;
				regulator-max-microvolt = <2800000>;
			};

			_ldo13_reg: s2mpb02-ldo13 {
				regulator-name = "VDDA_2.8V_VT";
				regulator-min-microvolt = <2800000>;
				regulator-max-microvolt = <2800000>;
			};

			_ldo14_reg: s2mpb02-ldo14 {
				regulator-name = "VDDAF_COMMON_CAM";
				regulator-min-microvolt = <3300000>;
				regulator-max-microvolt = <3300000>;
			};

			_ldo15_reg: s2mpb02-ldo15 {
				regulator-name = "VDDD_2.8V_OIS";
				regulator-min-microvolt = <2800000>;
				regulator-max-microvolt = <2800000>;
			};

			_ldo16_reg: s2mpb02-ldo16 {
				regulator-name = "VDDAF_2.8V_VT";
				regulator-min-microvolt = <2800000>;
				regulator-max-microvolt = <2800000>;
			};

			_ldo17_reg: s2mpb02-ldo17 {
				regulator-name = "S2MPB02_LDO17";
				regulator-min-microvolt = <2950000>;
				regulator-max-microvolt = <2950000>;
			};

			_ldo18_reg: s2mpb02-ldo18 {
				regulator-name = "VDD_PROXY_LED_3P3";
				regulator-min-microvolt = <3300000>;
				regulator-max-microvolt = <3300000>;
			};
		};

		torch {
			torch1-gpio = <&gpg2 4 0x1>;
			flash1-gpio = <&gpg3 5 0x1>;

			status = "okay";

			leds1 {
				ledname = "leds-sec1";
				id = <0>;
				brightness = <0xC>; /* Nx100+50 : 1250mA */
				timeout = <0x7>; /* (N+1)x62.5 : 500ms */
				torch_table_enable = <0>;
			};

			leds2 {
				ledname = "torch-sec1";
				id = <1>;
				brightness = <0xC>; /* Nx20 = 240mA */
				timeout = <0xF>;
				torch_table_enable = <1>;
				torch_table = <2 3 3 4 4 7 7 7 9 9>; /* [0],[1],[3],[5],[8] */
			};
		};
	};
};

&hsi2c_39 {
	#address-cells = <1>;
	#size-cells = <0>;
	status = "okay";
	s2dos05_pmic@60 {
		compatible = "samsung,s2dos05pmic";
		reg = <0x60>;
		s2dos05,wakeup;
		pinctrl-names = "default";
		pinctrl-0 = <&dp_pmic_irq>;
		s2dos05,s2dos05_int = <&gpa1 4 0>;
		adc_mode = <1>; /* 0 : disable, 1 : current meter, 2 : power meter */
		adc_sync_mode = <2>; /* 1 : sync mode, 2 : async mode */
		regulators {
			dp_buck: s2dos05-buck1 {
				regulator-name = "vdd1";
				regulator-min-microvolt = <850000>;
				regulator-max-microvolt = <2100000>;
				regulator-always-on;
				regulator-boot-on;
			};
			dp_ldo1: s2dos05-ldo1 {
				regulator-name = "vdd2";
				regulator-min-microvolt = <1500000>;
				regulator-max-microvolt = <2000000>;
				regulator-always-on;
				regulator-boot-on;
			};
			dp_ldo2: s2dos05-ldo2 {
				regulator-name = "vdd3";
				regulator-min-microvolt = <1500000>;
				regulator-max-microvolt = <2000000>;
				regulator-always-on;
				regulator-boot-on;
			};
			dp_ldo3: s2dos05-ldo3{
				regulator-name = "vdd4";
				regulator-min-microvolt = <2700000>;
				regulator-max-microvolt = <3775000>;
				regulator-always-on;
				regulator-boot-on;
			};
			dp_ldo4: s2dos05-ldo4{
				regulator-name = "vdd5";
				regulator-min-microvolt = <2700000>;
				regulator-max-microvolt = <3775000>;
				regulator-always-on;
				regulator-boot-on;
			};
		};
	};
};

&abox_gic {
	status = "okay";
};

&abox {
	status = "okay";
};

&spi_2 {
	#address-cells = <1>;
	#size-cells = <0>;
	status = "okay";
	pinctrl-names = "default";
	pinctrl-0 = <&spi2_bus &spi2_cs_func>;

	cs47l93: cs47l93@0 {
		compatible = "cirrus,cs47l93";
		reg = <0x0>;

		spi-max-frequency = <25000000>;

		interrupts = <2 0 0>;
		interrupt-controller;
		#interrupt-cells = <2>;
		interrupt-parent = <&gpa2>;
		gpio-controller;
		#gpio-cells = <2>;
		#sound-dai-cells = <1>;

		AVDD-supply = <&ldo33_reg>;
		DBVDD1-supply = <&ldo33_reg>;
		CPVDD1-supply = <&ldo33_reg>;
		CPVDD2-supply = <&ldo34_reg>;
		DCVDD-supply = <&ldo34_reg>;

		reset-gpios = <&gpg1 0 0>;

		cirrus,dmic-ref = <1 1 1 1>;
		cirrus,inmode = <
			2 2 1 0 /* IN1 */
			2 2 0 0 /* IN2 */
		>;
		cirrus,outmono = <0 0 0 1 0 0>;

		pinctrl-names = "default";
		pinctrl-0 = <&codec_reset>;

		cirrus,gpsw = <1 0>;

		cs47l93_defaults: cs47l93-gpio-defaults {
			aif1 {
				groups = "aif1";
				function = "aif1";
				bias-bus-hold;
			};

			aif2 {
				groups = "aif2";
				function = "aif2";
				bias-bus-hold;
			};

			aif3 {
				groups = "aif3";
				function = "aif3";
				bias-bus-hold;
			};
		};

		MICBIAS1 {
			regulator-min-microvolt = <1800000>;
			regulator-max-microvolt = <1800000>;
			cirrus,ext-cap = <1>;
		};
		MICBIAS1A {
			regulator-active-discharge = <1>;
		};
		MICBIAS1B {
			regulator-active-discharge = <1>;
		};
		MICBIAS1C {
			regulator-active-discharge = <1>;
		};
		MICBIAS2 {
			regulator-min-microvolt = <2800000>;
			regulator-max-microvolt = <2800000>;
			cirrus,ext-cap = <1>;
		};
		MICBIAS2A {
			regulator-active-discharge = <1>;
		};

		cirrus,accdet {
			#address-cells = <1>;
			#size-cells = <0>;

			acc@1 {
				reg = <1>;

				cirrus,micd-bias-start-time = <0x1>;
				cirrus,micd-rate = <7>;
				cirrus,micd-detect-debounce-ms = <300>;
				cirrus,micd-clamp-mode = <0x8>;
				cirrus,jd-use-jd2;

				cirrus,init-delay-ms = <30>;
				cirrus,micd-dbtime = <0x1>;
				cirrus,micd-timeout-ms = <1000>;
				cirrus,micd-force-micbias;
				cirrus,hpdet-short-circuit-imp = <3>;
				cirrus,micd-pol-gpios = <&cs47l93 4 0>;
				cirrus,micd-ranges = <
					116 226
					173 582
					321 115
					752 114
					1257 217
				>;
				cirrus,micd-software-compare;
				cirrus,micd-open-circuit-declare = <1>;
				cirrus,jd-wake-time = <5000>;

				cirrus,moisture-pin = <7>;
				cirrus,moisture-imp = <2000>;
				cirrus,moisture-debounce = <4>;

				cirrus,micd-configs = <
					0 1 4 0 1
				>;
			};
		};

		controller-data {
			samsung,spi-feedback-delay = <1>;
			samsung,spi-chip-select-mode = <0>;
		};
	};
};

&hsi2c_18 {
	#address-cells = <1>;
	#size-cells = <0>;
	status = "okay";
	clock-frequency = <1000000>;
	max98512: max98512@3a {
		compatible = "maxim,max98512";
		#sound-dai-cells = <1>;
		reg = <0x3a>;
		maxim,spk-gain = <0x05>;
		maxim,sysclk = <12288000>;
		maxim,vmon_slot = <0>;
		maxim,platform_info = <2 0x0 0x0 0x0 0x0 42>;
		maxim,boost_step = <
			0x0F 0x0F 0x0F 0x0F
			0x0F 0x0F 0x0F 0x0F
			0x0F 0x0F 0x0F 0x0F
			0x0F 0x0F 0x02 0x00
			>;
		maxim,adc_threshold = <7>;
		maxim,registers-of-amp =
			<0x1F 0x00>,
			<0x21 0xC0>,
			<0x2D 0x14>,
			<0x2F 0x00>;
		maxim,sub_reg = <0x39>;
		maxim,mono_stereo = <1>;
		interleave_mode = <1>;
	};
};
&hsi2c_10 {
	#address-cells = <1>;
	#size-cells = <0>;
	status = "okay";
	samsung,reset-before-trans;
	touchscreen@48 {
		compatible = "sec,sec_ts";
		reg = <0x48>;
		pinctrl-names = "on_state", "off_state";
		pinctrl-0 = <&attn_irq>;
		pinctrl-1 = <&attn_input>;
		pressure-sensor = "Y";
		sec,irq_gpio = <&gpa1 0 0>;
		sec,irq_type = <8200>;
		sec,max_coords = <4095 4095>;
		sec,mis_cal_check = <1>;
		sec,regulator_dvdd = "tsp_io";
		sec,regulator_avdd = "tsp_avdd";
		sec,regulator_boot_on;
		sec,always_lpmode = <1>;
		//sec,pat_function = <2>;
		//sec,afe_base = <0x0121>;
		sec,project_name = "Star1", "G950";
		sec,firmware_name = "tsp_sec/y761_dream1.fw", "tsp_sec/y761_dream1.fw";
		//support_dex_mode;
	};
};

&pinctrl_2 {
	phy_port: phy-port {
		samsung,pins = "gph0-6";
		samsung,pin-function = <0x0>;
		samsung,pin-pud = <3>;
		samsung,pin-drv = <0>;
	};
};

&udc {
	status = "okay";
};

&usbdrd_dwc3 {
	dr_mode = "otg";
	maximum-speed = "super-speed";
	snps,quirk-frame-length-adjustment = <0x20>;
	snps,u1u2_exitfail_quirk;
	/*
	 * dis-u2-freeclk-exists-quirk, dis_u2_susphy_quirk are alternative.
	 * One of them should be selected
	 */
	/*snps,dis-u2-freeclk-exists-quirk;*/
	snps,dis_u2_susphy_quirk;
};

&usbdrd_phy0 {
	status = "okay";

	pinctrl-names = "default";
	pinctrl-0 = <&phy_port>;
	phy,gpio_phy_port = <&gph0 6 0x0>;
	hs_tune_param = <&usb_hs_tune>;
	ss_tune_param = <&usb_ss_tune>;
};

/* SPI USI_PERIC1_SPI_CAM0 */
&spi_0 {
	#address-cells = <1>;
	#size-cells = <0>;
	pinctrl-names = "default", "spi_out", "spi_fn";
	pinctrl-0 = <&fimc_is_spi_pin0_out>;
	pinctrl-1 = <&fimc_is_spi_pin0_out>;
	pinctrl-2 = <&fimc_is_spi_pin0_fn>;
	status = "okay";

	num-cs = <1>;

	fimc_is_spi_0@0 {
		compatible = "samsung,fimc_is_spi0";
		spi-max-frequency = <50000000>;
		reg = <0x0>;
		pinctrl-names = "default", "ssn_out", "ssn_fn", "ssn_inpd", "ssn_inpu";
		pinctrl-0 = <&fimc_is_spi_ssn0_out>;
		pinctrl-1 = <&fimc_is_spi_ssn0_out>;
		pinctrl-2 = <&fimc_is_spi_ssn0_fn>;
		pinctrl-3 = <&fimc_is_spi_ssn0_inpd>;
		pinctrl-4 = <&fimc_is_spi_ssn0_inpu>;

		use_spi_pinctrl; /* define if camera use spi */

		controller-data {
			samsung,spi-chip-select-mode = <0>;
			samsung,spi-feedback-delay = <1>;
		};
	};
};

&fimc_is {
	vender {
		rear_sensor_id = <36>; /* 2L3 : 36 */
		front_sensor_id = <31>; /* 3H1 : 31 */
		rear_second_sensor_id = <33>; /* 3M3 : 33 */
		secure_sensor_id = <306>; /* 5F1 : 306 */
		use_module_check;
		use_ois;
		/*skip_cal_loading;*/
		check_sensor_vendor;
		ois_sensor_index = <0>;
		aperture_sensor_index = <0>;

		max_camera_num = <4>;
		camera_info0 {			// 0 : rear
			isp = <0>;		/* 0 : INT , 1 : EXT , 2 : SOC */
			cal_memory = <1>;	/* 0 : N , 1 : FROM , 2 : EEPROM , 3 : OTP  */
			read_version = <0>;	/* 0 : SYSFS , 1 : CAMON */
			core_voltage = <0>;	/* 0 : N , 1 : Y  */
			upgrade = <0>;		/* 0 : N , 1 : SYSFS , 2 : CAMON */
			fw_write = <0>;		/* 0 : N,  1 : OS, 2 : SD, 3 : ALL */
			fw_dump = <0>;		/* 0 : N , 1 : Y  */
			companion = <0>;	/* 0 : N , 1 : Y  */
			ois = <1>;		/* 0 : N , 1 : Y  */
			valid = <1>;		/* 0 : INVALID , 1 : VALID   */
		};
		camera_info1 {			// 1 : front
			isp = <0>;		/* 0 : INT , 1 : EXT , 2 : SOC */
			cal_memory = <2>;	/* 0 : N , 1 : FROM , 2 : EEPROM , 3 : OTP  */
			read_version = <0>;	/* 0 : SYSFS , 1 : CAMON */
			core_voltage = <0>;	/* 0 : N , 1 : Y  */
			upgrade = <0>;		/* 0 : N , 1 : SYSFS , 2 : CAMON */
			fw_write = <0>;		/* 0 : N,  1 : OS, 2 : SD, 3 : ALL */
			fw_dump = <0>;		/* 0 : N , 1 : Y  */
			companion = <0>;	/* 0 : N , 1 : Y  */
			ois = <0>;		/* 0 : N , 1 : Y  */
			valid = <1>;		/* 0 : INVALID , 1 : VALID   */
		};
		camera_info2 {			// 2 : tele
			isp = <0>;              /* 0 : INT , 1 : EXT , 2 : SOC */
			cal_memory = <1>;       /* 0 : N , 1 : FROM , 2 : EEPROM , 3 : OTP  */
			read_version = <0>;     /* 0 : SYSFS , 1 : CAMON */
			core_voltage = <0>;     /* 0 : N , 1 : Y  */
			upgrade = <0>;          /* 0 : N , 1 : SYSFS , 2 : CAMON */
			fw_write = <0>;         /* 0 : N,  1 : OS, 2 : SD, 3 : ALL */
			fw_dump = <0>;          /* 0 : N , 1 : Y  */
			companion = <0>;        /* 0 : N , 1 : Y  */
			ois = <1>;              /* 0 : N , 1 : Y  */
			valid = <1>;            /* 0 : INVALID , 1 : VALID   */
		};
		camera_info3 {			// 3 : iris
			isp = <2>;		/* 0 : INT , 1 : EXT , 2 : SOC */
			cal_memory = <0>;	/* 0 : N , 1 : FROM , 2 : EEPROM , 3 : OTP  */
			read_version = <1>;	/* 0 : SYSFS , 1 : CAMON */
			core_voltage = <0>;	/* 0 : N , 1 : Y  */
			upgrade = <0>;		/* 0 : N , 1 : SYSFS , 2 : CAMON */
			fw_write = <0>;		/* 0 : N,  1 : OS, 2 : SD, 3 : ALL */
			fw_dump = <0>;		/* 0 : N , 1 : Y  */
			companion = <0>;	/* 0 : N , 1 : Y  */
			ois = <0>;		/* 0 : N , 1 : Y  */
			valid = <1>;		/* 0 : INVALID , 1 : VALID   */
		};
	};

	fimc_is_dvfs {
		#define DVFS_INT_CAM_L0 690000
		#define DVFS_INT_CAM_L1 680000
		#define DVFS_INT_CAM_L2 670000
		#define DVFS_INT_CAM_L3 660000
		#define DVFS_INT_CAM_L4 650000
		#define DVFS_INT_CAM_L5 640000
		#define DVFS_INT_CAM_L6 630000

		#define DVFS_INT_L0 534000
		#define DVFS_INT_L1 400000
		#define DVFS_INT_L2 336000
		#define DVFS_INT_L3 267000
		#define DVFS_INT_L4 178000
		#define DVFS_INT_L5 107000

		#define DVFS_CAM_L0 690000
		#define DVFS_CAM_L1 680000
		#define DVFS_CAM_L2 670000
		#define DVFS_CAM_L3 660000
		#define DVFS_CAM_L4 650000
		#define DVFS_CAM_L5 640000
		#define DVFS_CAM_L6 630000
		#define DVFS_CAM_L7 620000
		#define DVFS_CAM_L8 610000
		#define DVFS_CAM_L9 600000
		#define DVFS_CAM_L10 590000

		#define DVFS_MIF_L0 2093000
		#define DVFS_MIF_L1 2093000
		#define DVFS_MIF_L2 2002000
		#define DVFS_MIF_L3 1794000
		#define DVFS_MIF_L4 1539000
		#define DVFS_MIF_L5 1352000
		#define DVFS_MIF_L6 1014000
		#define DVFS_MIF_L7 845000
		#define DVFS_MIF_L8 676000
		#define DVFS_MIF_L9 546000
		#define DVFS_MIF_L10 421000

		table0 {
			desc = "dvfs table v0.0 for 12M/8M";

			default_int_cam = <DVFS_INT_CAM_L0>;
			default_cam = <DVFS_CAM_L0>;
			default_mif = <DVFS_MIF_L0>;
			default_int = <DVFS_INT_L5>;
			default_hpg = <1>;

			front_preview_int_cam = <DVFS_INT_CAM_L5>;
			front_preview_cam = <DVFS_CAM_L9>;
			front_preview_mif = <DVFS_MIF_L6>;
			front_preview_int = <DVFS_INT_L5>;
			front_preview_hpg = <1>;

			front_preview_full_int_cam = <DVFS_INT_CAM_L3>;
			front_preview_full_cam = <DVFS_CAM_L9>;
			front_preview_full_mif = <DVFS_MIF_L6>;
			front_preview_full_int = <DVFS_INT_L5>;
			front_preview_full_hpg = <1>;

			front_capture_int_cam = <DVFS_INT_CAM_L3>;
			front_capture_cam = <DVFS_CAM_L9>;
			front_capture_mif = <DVFS_MIF_L6>;
			front_capture_int = <DVFS_INT_L5>;
			front_capture_hpg = <1>;

			front_video_int_cam = <DVFS_INT_CAM_L5>;
			front_video_cam = <DVFS_CAM_L9>;
			front_video_mif = <DVFS_MIF_L6>;
			front_video_int = <DVFS_INT_L5>;
			front_video_hpg = <1>;

			front_video_whd_int_cam = <DVFS_INT_CAM_L5>;
			front_video_whd_cam = <DVFS_CAM_L9>;
			front_video_whd_mif = <DVFS_MIF_L6>;
			front_video_whd_int = <DVFS_INT_L5>;
			front_video_whd_hpg = <1>;

			front_video_capture_int_cam = <DVFS_INT_CAM_L3>;
			front_video_capture_cam = <DVFS_CAM_L8>;
			front_video_capture_mif = <DVFS_MIF_L6>;
			front_video_capture_int = <DVFS_INT_L5>;
			front_video_capture_hpg = <1>;

			front_video_whd_capture_int_cam = <DVFS_INT_CAM_L3>;
			front_video_whd_capture_cam = <DVFS_CAM_L9>;
			front_video_whd_capture_mif = <DVFS_MIF_L6>;
			front_video_whd_capture_int = <DVFS_INT_L5>;
			front_video_whd_capture_hpg = <1>;

			front_vt1_int_cam = <DVFS_INT_CAM_L5>;
			front_vt1_cam = <DVFS_CAM_L9>;
			front_vt1_mif = <DVFS_MIF_L6>;
			front_vt1_int = <DVFS_INT_L5>;
			front_vt1_hpg = <1>;

			front_vt2_int_cam = <DVFS_INT_CAM_L5>;
			front_vt2_cam = <DVFS_CAM_L9>;
			front_vt2_mif = <DVFS_MIF_L6>;
			front_vt2_int = <DVFS_INT_L5>;
			front_vt2_hpg = <1>;

			front_vt4_int_cam = <DVFS_INT_CAM_L5>;
			front_vt4_cam = <DVFS_CAM_L9>;
			front_vt4_mif = <DVFS_MIF_L6>;
			front_vt4_int = <DVFS_INT_L5>;
			front_vt4_hpg = <1>;

			front_preview_high_speed_fps_int_cam = <DVFS_INT_CAM_L3>;
			front_preview_high_speed_fps_cam = <DVFS_CAM_L8>;
			front_preview_high_speed_fps_mif = <DVFS_MIF_L6>;
			front_preview_high_speed_fps_int = <DVFS_INT_L5>;
			front_preview_high_speed_fps_hpg = <1>;

			rear2_preview_fhd_int_cam = <DVFS_INT_CAM_L5>;
			rear2_preview_fhd_cam = <DVFS_CAM_L5>;
			rear2_preview_fhd_mif = <DVFS_MIF_L6>;
			rear2_preview_fhd_int = <DVFS_INT_L5>;
			rear2_preview_fhd_hpg = <1>;

			rear2_capture_int_cam = <DVFS_INT_CAM_L3>;
			rear2_capture_cam = <DVFS_CAM_L5>;
			rear2_capture_mif = <DVFS_MIF_L6>;
			rear2_capture_int = <DVFS_INT_L5>;
			rear2_capture_hpg = <1>;

			rear2_video_fhd_int_cam = <DVFS_INT_CAM_L5>;
			rear2_video_fhd_cam = <DVFS_CAM_L5>;
			rear2_video_fhd_mif = <DVFS_MIF_L6>;
			rear2_video_fhd_int = <DVFS_INT_L5>;
			rear2_video_fhd_hpg = <1>;

			rear2_video_fhd_capture_int_cam = <DVFS_INT_CAM_L3>;
			rear2_video_fhd_capture_cam = <DVFS_CAM_L5>;
			rear2_video_fhd_capture_mif = <DVFS_MIF_L6>;
			rear2_video_fhd_capture_int = <DVFS_INT_L5>;
			rear2_video_fhd_capture_hpg = <1>;

			rear_preview_fhd_int_cam = <DVFS_INT_CAM_L5>;
			rear_preview_fhd_cam = <DVFS_CAM_L5>;
			rear_preview_fhd_mif = <DVFS_MIF_L6>;
			rear_preview_fhd_int = <DVFS_INT_L5>;
			rear_preview_fhd_hpg = <1>;

			rear_preview_whd_int_cam = <DVFS_INT_CAM_L5>;
			rear_preview_whd_cam = <DVFS_CAM_L5>;
			rear_preview_whd_mif = <DVFS_MIF_L6>;
			rear_preview_whd_int = <DVFS_INT_L5>;
			rear_preview_whd_hpg = <1>;

			rear_preview_uhd_int_cam = <DVFS_INT_CAM_L3>;
			rear_preview_uhd_cam = <DVFS_CAM_L5>;
			rear_preview_uhd_mif = <DVFS_MIF_L6>;
			rear_preview_uhd_int = <DVFS_INT_L5>;
			rear_preview_uhd_hpg = <1>;

			rear_preview_uhd_60fps_int_cam = <DVFS_INT_CAM_L1>;
			rear_preview_uhd_60fps_cam = <DVFS_CAM_L5>;
			rear_preview_uhd_60fps_mif = <DVFS_MIF_L3>;
			rear_preview_uhd_60fps_int = <DVFS_INT_L5>;
			rear_preview_uhd_60fps_hpg = <1>;

			rear_preview_full_int_cam = <DVFS_INT_CAM_L3>;
			rear_preview_full_cam = <DVFS_CAM_L5>;
			rear_preview_full_mif = <DVFS_MIF_L5>;
			rear_preview_full_int = <DVFS_INT_L5>;
			rear_preview_full_hpg = <1>;

			rear_capture_int_cam = <DVFS_INT_CAM_L3>;
			rear_capture_cam = <DVFS_CAM_L5>;
			rear_capture_mif = <DVFS_MIF_L6>;
			rear_capture_int = <DVFS_INT_L5>;
			rear_capture_hpg = <1>;

			rear_video_fhd_int_cam = <DVFS_INT_CAM_L5>;
			rear_video_fhd_cam = <DVFS_CAM_L5>;
			rear_video_fhd_mif = <DVFS_MIF_L6>;
			rear_video_fhd_int = <DVFS_INT_L5>;
			rear_video_fhd_hpg = <1>;

			rear_video_whd_int_cam = <DVFS_INT_CAM_L5>;
			rear_video_whd_cam = <DVFS_CAM_L5>;
			rear_video_whd_mif = <DVFS_MIF_L6>;
			rear_video_whd_int = <DVFS_INT_L5>;
			rear_video_whd_hpg = <1>;

			rear_video_uhd_int_cam = <DVFS_INT_CAM_L3>;
			rear_video_uhd_cam = <DVFS_CAM_L5>;
			rear_video_uhd_mif = <DVFS_MIF_L6>;
			rear_video_uhd_int = <DVFS_INT_L5>;
			rear_video_uhd_hpg = <1>;

			rear_video_uhd_60fps_int_cam = <DVFS_INT_CAM_L1>;
			rear_video_uhd_60fps_cam = <DVFS_CAM_L5>;
			rear_video_uhd_60fps_mif = <DVFS_MIF_L3>;
			rear_video_uhd_60fps_int = <DVFS_INT_L5>;
			rear_video_uhd_60fps_hpg = <1>;

			rear_video_fhd_capture_int_cam = <DVFS_INT_CAM_L3>;
			rear_video_fhd_capture_cam = <DVFS_CAM_L5>;
			rear_video_fhd_capture_mif = <DVFS_MIF_L6>;
			rear_video_fhd_capture_int = <DVFS_INT_L5>;
			rear_video_fhd_capture_hpg = <1>;

			rear_video_whd_capture_int_cam = <DVFS_INT_CAM_L3>;
			rear_video_whd_capture_cam = <DVFS_CAM_L5>;
			rear_video_whd_capture_mif = <DVFS_MIF_L6>;
			rear_video_whd_capture_int = <DVFS_INT_L5>;
			rear_video_whd_capture_hpg = <1>;

			rear_video_uhd_capture_int_cam = <DVFS_INT_CAM_L3>;
			rear_video_uhd_capture_cam = <DVFS_CAM_L5>;
			rear_video_uhd_capture_mif = <DVFS_MIF_L6>;
			rear_video_uhd_capture_int = <DVFS_INT_L5>;
			rear_video_uhd_capture_hpg = <1>;

			dual_preview_int_cam = <DVFS_INT_CAM_L5>;
			dual_preview_cam = <DVFS_CAM_L5>;
			dual_preview_mif = <DVFS_MIF_L6>;
			dual_preview_int = <DVFS_INT_L5>;
			dual_preview_hpg = <1>;

			dual_capture_int_cam = <DVFS_INT_CAM_L3>;
			dual_capture_cam = <DVFS_CAM_L5>;
			dual_capture_mif = <DVFS_MIF_L6>;
			dual_capture_int = <DVFS_INT_L5>;
			dual_capture_hpg = <1>;

			dual_video_fhd_int_cam = <DVFS_INT_CAM_L5>;
			dual_video_fhd_cam = <DVFS_CAM_L5>;
			dual_video_fhd_mif = <DVFS_MIF_L6>;
			dual_video_fhd_int = <DVFS_INT_L5>;
			dual_video_fhd_hpg = <1>;

			dual_video_fhd_capture_int_cam = <DVFS_INT_CAM_L3>;
			dual_video_fhd_capture_cam = <DVFS_CAM_L5>;
			dual_video_fhd_capture_mif = <DVFS_MIF_L6>;
			dual_video_fhd_capture_int = <DVFS_INT_L5>;
			dual_video_fhd_capture_hpg = <1>;

			dual_video_uhd_int_cam = <DVFS_INT_CAM_L3>;
			dual_video_uhd_cam = <DVFS_CAM_L5>;
			dual_video_uhd_mif = <DVFS_MIF_L6>;
			dual_video_uhd_int = <DVFS_INT_L5>;
			dual_video_uhd_hpg = <1>;

			dual_video_uhd_capture_int_cam = <DVFS_INT_CAM_L3>;
			dual_video_uhd_capture_cam = <DVFS_CAM_L5>;
			dual_video_uhd_capture_mif = <DVFS_MIF_L6>;
			dual_video_uhd_capture_int = <DVFS_INT_L5>;
			dual_video_uhd_capture_hpg = <1>;

			dual_sync_preview_int_cam = <DVFS_INT_CAM_L3>;
			dual_sync_preview_cam = <DVFS_CAM_L5>;
			dual_sync_preview_mif = <DVFS_MIF_L4>;
			dual_sync_preview_int = <DVFS_INT_L5>;
			dual_sync_preview_hpg = <1>;

			dual_sync_capture_int_cam = <DVFS_INT_CAM_L2>;
			dual_sync_capture_cam = <DVFS_CAM_L5>;
			dual_sync_capture_mif = <DVFS_MIF_L3>;
			dual_sync_capture_int = <DVFS_INT_L5>;
			dual_sync_capture_hpg = <1>;

			dual_sync_preview_whd_int_cam = <DVFS_INT_CAM_L1>;
			dual_sync_preview_whd_cam = <DVFS_CAM_L5>;
			dual_sync_preview_whd_mif = <DVFS_MIF_L3>;
			dual_sync_preview_whd_int = <DVFS_INT_L5>;
			dual_sync_preview_whd_hpg = <1>;

			dual_sync_whd_capture_int_cam = <DVFS_INT_CAM_L1>;
			dual_sync_whd_capture_cam = <DVFS_CAM_L5>;
			dual_sync_whd_capture_mif = <DVFS_MIF_L3>;
			dual_sync_whd_capture_int = <DVFS_INT_L5>;
			dual_sync_whd_capture_hpg = <1>;

			dual_sync_video_fhd_int_cam = <DVFS_INT_CAM_L3>;
			dual_sync_video_fhd_cam = <DVFS_CAM_L5>;
			dual_sync_video_fhd_mif = <DVFS_MIF_L4>;
			dual_sync_video_fhd_int = <DVFS_INT_L5>;
			dual_sync_video_fhd_hpg = <1>;

			dual_sync_video_fhd_capture_int_cam = <DVFS_INT_CAM_L2>;
			dual_sync_video_fhd_capture_cam = <DVFS_CAM_L5>;
			dual_sync_video_fhd_capture_mif = <DVFS_MIF_L3>;
			dual_sync_video_fhd_capture_int = <DVFS_INT_L5>;
			dual_sync_video_fhd_capture_hpg = <1>;

			dual_sync_video_uhd_int_cam = <DVFS_INT_CAM_L1>;
			dual_sync_video_uhd_cam = <DVFS_CAM_L5>;
			dual_sync_video_uhd_mif = <DVFS_MIF_L4>;
			dual_sync_video_uhd_int = <DVFS_INT_L5>;
			dual_sync_video_uhd_hpg = <1>;

			dual_sync_video_uhd_capture_int_cam = <DVFS_INT_CAM_L1>;
			dual_sync_video_uhd_capture_cam = <DVFS_CAM_L5>;
			dual_sync_video_uhd_capture_mif = <DVFS_MIF_L3>;
			dual_sync_video_uhd_capture_int = <DVFS_INT_L5>;
			dual_sync_video_uhd_capture_hpg = <1>;

			secure_front_int_cam = <DVFS_INT_CAM_L5>;
			secure_front_cam = <DVFS_CAM_L8>;
			secure_front_mif = <DVFS_MIF_L6>;
			secure_front_int = <DVFS_INT_L5>;
			secure_front_hpg = <1>;

			pip_preview_int_cam = <DVFS_INT_CAM_L3>;
			pip_preview_cam = <DVFS_CAM_L5>;
			pip_preview_mif = <DVFS_MIF_L6>;
			pip_preview_int = <DVFS_INT_L5>;
			pip_preview_hpg = <1>;

			pip_capture_int_cam = <DVFS_INT_CAM_L2>;
			pip_capture_cam = <DVFS_CAM_L5>;
			pip_capture_mif = <DVFS_MIF_L6>;
			pip_capture_int = <DVFS_INT_L5>;
			pip_capture_hpg = <1>;

			pip_video_int_cam = <DVFS_INT_CAM_L3>;
			pip_video_cam = <DVFS_CAM_L5>;
			pip_video_mif = <DVFS_MIF_L6>;
			pip_video_int = <DVFS_INT_L5>;
			pip_video_hpg = <1>;

			pip_video_capture_int_cam = <DVFS_INT_CAM_L2>;
			pip_video_capture_cam = <DVFS_CAM_L5>;
			pip_video_capture_mif = <DVFS_MIF_L6>;
			pip_video_capture_int = <DVFS_INT_L5>;
			pip_video_capture_hpg = <1>;

			preview_high_speed_fps_int_cam = <DVFS_INT_CAM_L3>;
			preview_high_speed_fps_cam = <DVFS_CAM_L5>;
			preview_high_speed_fps_mif = <DVFS_MIF_L6>;
			preview_high_speed_fps_int = <DVFS_INT_L5>;
			preview_high_speed_fps_hpg = <1>;

			video_high_speed_60fps_int_cam = <DVFS_INT_CAM_L3>;
			video_high_speed_60fps_cam = <DVFS_CAM_L5>;
			video_high_speed_60fps_mif = <DVFS_MIF_L5>;
			video_high_speed_60fps_int = <DVFS_INT_L5>;
			video_high_speed_60fps_hpg = <1>;

			video_high_speed_120fps_int_cam = <DVFS_INT_CAM_L3>;
			video_high_speed_120fps_cam = <DVFS_CAM_L5>;
			video_high_speed_120fps_mif = <DVFS_MIF_L6>;
			video_high_speed_120fps_int = <DVFS_INT_L5>;
			video_high_speed_120fps_hpg = <1>;

			video_high_speed_240fps_int_cam = <DVFS_INT_CAM_L1>;
			video_high_speed_240fps_cam = <DVFS_CAM_L5>;
			video_high_speed_240fps_mif = <DVFS_MIF_L3>;
			video_high_speed_240fps_int = <DVFS_INT_L5>;
			video_high_speed_240fps_hpg = <1>;

			video_high_speed_dualfps_int_cam = <DVFS_INT_CAM_L1>;
			video_high_speed_dualfps_cam = <DVFS_CAM_L5>;
			video_high_speed_dualfps_mif = <DVFS_MIF_L3>;
			video_high_speed_dualfps_int = <DVFS_INT_L5>;
			video_high_speed_dualfps_hpg = <6>;

			video_high_speed_60fps_capture_int_cam = <DVFS_INT_CAM_L3>;
			video_high_speed_60fps_capture_cam = <DVFS_CAM_L5>;
			video_high_speed_60fps_capture_mif = <DVFS_MIF_L5>;
			video_high_speed_60fps_capture_int = <DVFS_INT_L5>;
			video_high_speed_60fps_capture_hpg = <1>;

			ext_front_int_cam = <DVFS_INT_CAM_L0>;
			ext_front_cam = <DVFS_CAM_L0>;
			ext_front_mif = <DVFS_MIF_L0>;
			ext_front_int = <DVFS_INT_L0>;
			ext_front_hpg = <1>;

			ext_secure_int_cam = <DVFS_INT_CAM_L5>;
			ext_secure_cam = <DVFS_CAM_L8>;
			ext_secure_mif = <DVFS_MIF_L6>;
			ext_secure_int = <DVFS_INT_L5>;
			ext_secure_hpg = <1>;

			max_int_cam = <DVFS_INT_CAM_L0>;
			max_cam = <DVFS_CAM_L0>;
			max_mif = <DVFS_MIF_L0>;
			max_int = <DVFS_INT_L0>;
			max_hpg = <1>;
		};
	};
};

/* I2C_CAM0 */ /* SENSOR_CONTROL_I2C0 */
&hsi2c_0 {
	#address-cells = <1>;
	#size-cells = <0>;
	gpios = <&gpc0 0 0 &gpc0 1 0>;
	status = "okay";
	clock-frequency = <1000000>;
	samsung,reset-before-trans;
	samsung,hs-mode;

	pinctrl-names = "default","on_i2c","off_i2c";
	pinctrl-0 = <&hsi2c0_bus_in>;
	pinctrl-1 = <&hsi2c0_bus>;
	pinctrl-2 = <&hsi2c0_bus_in>;

	fimc-is-2l3@10 {
		compatible = "samsung,exynos5-fimc-is-cis-2l3";
		reg = <0x10>; /* 1 bit right shift */
		id = <0>; /* matching fimc_is_sensor id */
		setfile = "setB";
	};
};

/* I2C_CAM1 */ /* SENSOR_CONTROL_I2C1 */
&hsi2c_1 {
	#address-cells = <1>;
	#size-cells = <0>;
	gpios = <&gpc0 2 0 &gpc0 3 0>;
	status = "okay";
	clock-frequency = <400000>;
	samsung,reset-before-trans;

	pinctrl-names = "default","on_i2c","off_i2c";
	pinctrl-0 = <&hsi2c1_bus_in>;
	pinctrl-1 = <&hsi2c1_bus>;
	pinctrl-2 = <&hsi2c1_bus_in>;

	fimc-is-actuator@0C {
		compatible = "samsung,exynos5-fimc-is-actuator-ak737x";
		reg = <0x0C>;
		id = <0>; /* matching fimc_is_sensor id */
		/* AK7372: addr 0x03, data 0x0C */
		/* AK7371: addr 0x03, data 0x09 */
		/* STAR AK7371 or AK7374: addr 0xF3, data 0x0E */
		vendor_product_id = <0xF3 0x0E 0x03 0x09 0x03 0x0E>;
		vendor_first_pos = <120>;
		vendor_first_delay = <2000>;
	};

	ois@24 {
		compatible = "samsung,exynos5-fimc-is-ois-rumbaS6";
		reg = <0x24>;
		id = <0 2>;
	};

	aperture@4C {
		compatible = "samsung,exynos5-fimc-is-aperture-ak7372";
		reg = <0x4C>;
		id = <0>;
	};
};

/* I2C_CAM2 */ /* SENSOR_CONTROL_I2C2 */
&hsi2c_2 {
	#address-cells = <1>;
	#size-cells = <0>;
	gpios = <&gpc0 4 0 &gpc0 5 0>;
	status = "okay";
	clock-frequency = <400000>;
	samsung,reset-before-trans;

	pinctrl-names = "default","on_i2c","off_i2c";
	pinctrl-0 = <&hsi2c2_bus_in>;
	pinctrl-1 = <&hsi2c2_bus>;
	pinctrl-2 = <&hsi2c2_bus_in>;

	fimc-is-3m3@2D {
		compatible = "samsung,exynos5-fimc-is-cis-3m3";
		reg = <0x2D>; /* 1 bit right shift */
		id = <2>; /* matching fimc_is_sensor id */
		setfile = "setB";
	};
};

/* PERI1 CAM3 */ /* SENSOR_CONTROL_I2C3 */
&hsi2c_3 {
	#address-cells = <1>;
	#size-cells = <0>;
	gpios = <&gpc0 6 0 &gpc0 7 0>;
	status = "okay";
	clock-frequency = <400000>;
	samsung,reset-before-trans;

	pinctrl-names = "default","on_i2c","off_i2c";
	pinctrl-0 = <&hsi2c3_bus_in>;
	pinctrl-1 = <&hsi2c3_bus>;
	pinctrl-2 = <&hsi2c3_bus_in>;

	fimc-is-actuator@0F {
		compatible = "samsung,exynos5-fimc-is-actuator-ak737x";
		reg = <0x0F>;
		id = <2>; /* matching sensor id */
		/* AK7372: addr 0x03, data 0x0C */
		/* AK7371: addr 0x03, data 0x09 */
		/* STAR AK7371 or AK7374: addr 0xF3, data 0x0E */
		vendor_product_id = <0xF3 0x0E 0x03 0x09 0x03 0x0E>;
		vendor_first_pos = <120>;
		vendor_first_delay = <2000>;
	};
};

/* USI08_USI_I2C */ /* SENSOR_CONTROL_I2C4 */
&hsi2c_21 {
	#address-cells = <1>;
	#size-cells = <0>;
	gpios = <&gpp5 2 0 &gpp5 3 0>;
	status = "okay";
	clock-frequency = <400000>;
	samsung,reset-before-trans;

	pinctrl-names = "default","on_i2c","off_i2c";
	pinctrl-0 = <&hsi2c21_bus_in>;
	pinctrl-1 = <&hsi2c21_bus>;
	pinctrl-2 = <&hsi2c21_bus_in>;

	fimc-is-imx320@10 {
		compatible = "samsung,exynos5-fimc-is-cis-imx320";
		reg = <0x10>; /* 1 bit right shift */
		id = <1>; /* matching sensor id */
		setfile = "default";
	};

	fimc-is-3h1@35 {
		compatible = "samsung,exynos5-fimc-is-cis-3h1";
		reg = <0x35>; /* 1 bit right shift */
		id = <1>; /* matching fimc_is_sensor id */
		setfile = "default";
	};
};

/* USI09_USI */ /* SENSOR_CONTROL_I2C5 */
&hsi2c_22 {
	#address-cells = <1>;
	#size-cells = <0>;
	gpios = <&gpp5 4 0 &gpp5 5 0>;
	status = "okay";
	clock-frequency = <400000>;
	samsung,reset-before-trans;

	pinctrl-names = "default","on_i2c","off_i2c";
	pinctrl-0 = <&hsi2c22_bus_in>;
	pinctrl-1 = <&hsi2c22_bus>;
	pinctrl-2 = <&hsi2c22_bus_in>;

	fimc-is-actuator@0C {
		compatible = "samsung,exynos5-fimc-is-actuator-ak737x";
		reg = <0x0C>;
		id = <1>; /* matching fimc_is_sensor id */
		/* AK7372: addr 0x03, data 0x0C */
		/* AK7371: addr 0x03, data 0x09 */
		/* STAR AK7371 or AK7374: addr 0xF3, data 0x0E */
		vendor_product_id = <0x03 0x0C>;
		vendor_first_pos = <120>;
		vendor_first_delay = <10000>;
	};

	front_eeprom@51 {
		compatible = "samsung,front-eeprom-i2c";
		reg = <0x51>;
	};
};

/* USI07_USI_I2C */ /* SENSOR_CONTROL_I2C6 */
&hsi2c_19 {
	#address-cells = <1>;
	#size-cells = <0>;
	gpios = <&gpp4 6 0 &gpp4 7 0>;
	status = "okay";
	clock-frequency = <400000>;
	samsung,reset-before-trans;
	/* secure-mode;  flag for secure gpio recover function */

	pinctrl-names = "default","on_i2c","off_i2c";
	pinctrl-0 = <&hsi2c19_bus_in>;
	pinctrl-1 = <&hsi2c19_bus>;
	pinctrl-2 = <&hsi2c19_bus_in>;

	fimc-is-secure@10 {
		compatible = "samsung,sensor-module-5f1";

		pinctrl-names = "pin0", "pin1", "pin2", "release";
		pinctrl-0 = <>;
		pinctrl-1 = <&fimc_is_mclk2_out>;
		pinctrl-2 = <&fimc_is_mclk2_fn>;
		pinctrl-3 = <>;

		position = <3>;	/* Rear:0. Front:1. Rear_sub:2. Secure:3. */
		reg = <0x10>;
		id = <3>; /* fimc_is_sensor id */
		mclk_ch = <2>;
		sensor_i2c_ch = <6>; /* SENSOR_CONTROL_I2C6 */
		hw_version = <1>;

		gpio_mclk = <&gpc1 6 0x1>;
		gpio_reset = <&gpg2 3 0x1>; /* sensor reset */
		gpio_iris_en = <&gpg0 7 0x1>;
		status = "okay";
	};
};

&fimc_is_sensor0 {
	scenario = <SENSOR_SCENARIO_NORMAL>;	/* Normal, Vision, OIS etc */
	id = <0>;
	csi_ch = <0>;
	dma_ch = <0 0 0 0 0 4 4 4>;
	vc_ch = <0 1 2 3 0 0 1 2>;
	flite_ch = <FLITE_ID_NOTHING>;
	is_bns = <0>;
	use_ssvc2_internal;
	use_ssvc3_internal;
	status = "okay";
};

&fimc_is_sensor1 {
	scenario = <SENSOR_SCENARIO_NORMAL>;	/* Normal, Vision, OIS etc */
	id = <1>;
	csi_ch = <1>;
	dma_ch = <1 1 1 1>;
	vc_ch = <0 1 2 3>;
	flite_ch = <FLITE_ID_NOTHING>;
	is_bns = <0>;
	status = "okay";
};

&fimc_is_sensor2 {
	scenario = <SENSOR_SCENARIO_NORMAL>;	/* Normal, Vision, OIS etc */
	id = <2>;
	csi_ch = <2>;
	dma_ch = <2 2 2 2>;
	vc_ch = <0 1 2 3>;
	flite_ch = <FLITE_ID_NOTHING>;
	use_ssvc1_internal;
	is_bns = <0>;
	status = "okay";
};

&fimc_is_sensor3 {
	scenario = <SENSOR_SCENARIO_SECURE>;	/* Normal, Vision, OIS etc */
	id = <3>;
	csi_ch = <3>;
	dma_ch = <3 3 3 3>;
	vc_ch = <0 1 2 3>;
	flite_ch = <FLITE_ID_NOTHING>;
	is_bns = <0>;
	status = "okay";
};


